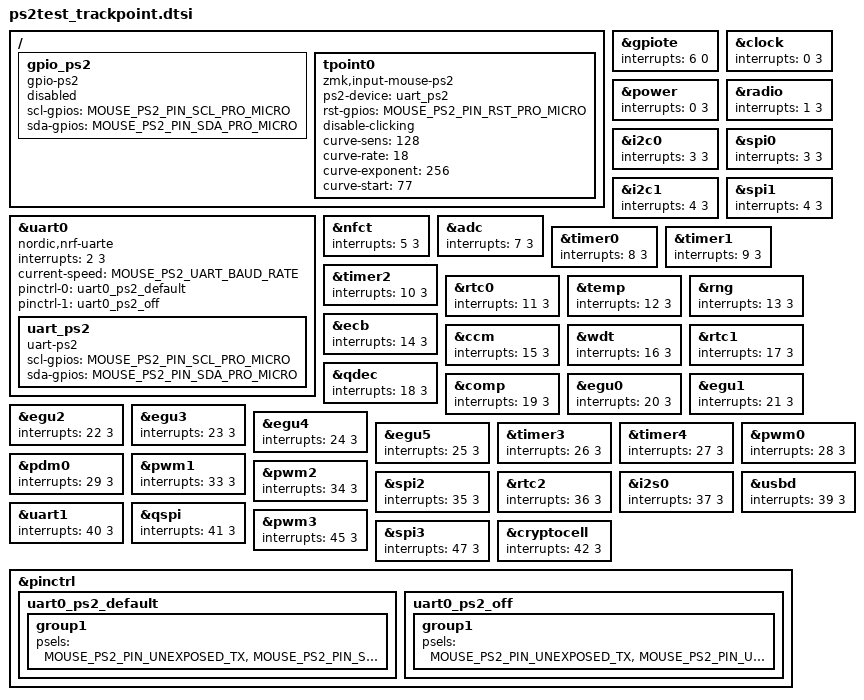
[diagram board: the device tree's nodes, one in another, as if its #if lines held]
/*
 * Direct PS/2 trackpoint wiring for the nice_nano v2 (Exp68 + Exp78).
 *
 * Exp78: switched to the uart-ps2 backend @ 19200 baud. The UART trick
 * glitched at 9600/14400 on THIS trackpoint (jittery RC clock), but 19200
 * was NEVER tried - this experiment is the clean test of that rate.
 * This TP rejects EVERY host command (Exp06): NO_HOST_COMMANDS stays on and
 * the driver never writes; all decode handling lives driver-side.
 *
 * Wiring (fixed empirically - the bench wiring is REVERSED vs stock dabao):
 *   TrackPoint DAT -> P0.08  (pro_micro 0)  = uart0 RX via pinctrl below
 *   TrackPoint CLK -> P0.06  (pro_micro 1)  = scl-gpios (GPIO input)
 *   TrackPoint RST -> float
 *
 * Pull-ups: PS/2 lines are open-drain; the uart backend pulls CLK
 * internally (patched in ps2_uart.c) and DAT idles high.
 */

#include <dt-bindings/pinctrl/nrf-pinctrl.h>

#define MOUSE_PS2_PIN_SCL_PRO_MICRO <&pro_micro 1 GPIO_ACTIVE_HIGH>
#define MOUSE_PS2_PIN_SDA_PRO_MICRO <&pro_micro 0 GPIO_ACTIVE_HIGH>
// #define MOUSE_PS2_PIN_RST_PRO_MICRO <&pro_micro 8 GPIO_ACTIVE_HIGH>

/* Exp78: uart-ps2 @ 19200 - the UART RX pin IS the PS/2 DAT line (P0.08).
 * UART TX / off-state pins are parked on unexposed P0.27: TX is never
 * exercised (NO_HOST_COMMANDS refuses every write) and the off state only
 * exists so the UARTE can release DAT if a write were ever attempted. */
#define MOUSE_PS2_PIN_SDA_PINCTRL <NRF_PSEL(UART_RX, 0, 8)>
#define MOUSE_PS2_UART_BAUD_RATE <19200>
#define MOUSE_PS2_PIN_UNEXPOSED_TX <NRF_PSEL(UART_TX, 0, 27)>
#define MOUSE_PS2_PIN_UNEXPOSED_RX <NRF_PSEL(UART_RX, 0, 27)>

// The Kconfig for both ps2 backends requires these interrupt-priority
// overrides: GPIOTE at the highest priority, everything else at 3, so BT
// controller interrupts never delay the PS/2 processing.
&gpiote { interrupts = < 6 0 >; };
&clock { interrupts = < 0 3 >; };
&power { interrupts = < 0 3 >; };
&radio { interrupts = < 1 3 >; };
&uart0 { interrupts = < 2 3 >; };
&i2c0 { interrupts = < 3 3 >; };
&spi0 { interrupts = < 3 3 >; };
&i2c1 { interrupts = < 4 3 >; };
&spi1 { interrupts = < 4 3 >; };
&nfct { interrupts = < 5 3 >; };
&adc { interrupts = < 7 3 >; };
&timer0 { interrupts = < 8 3 >; };
&timer1 { interrupts = < 9 3 >; };
&timer2 { interrupts = < 10 3 >; };
&rtc0 { interrupts = < 11 3 >; };
&temp { interrupts = < 12 3 >; };
&rng { interrupts = < 13 3 >; };
&ecb { interrupts = < 14 3 >; };
&ccm { interrupts = < 15 3 >; };
&wdt { interrupts = < 16 3 >; };
&rtc1 { interrupts = < 17 3 >; };
&qdec { interrupts = < 18 3 >; };
&comp { interrupts = < 19 3 >; };
&egu0 { interrupts = < 20 3 >; };
&egu1 { interrupts = < 21 3 >; };
&egu2 { interrupts = < 22 3 >; };
&egu3 { interrupts = < 23 3 >; };
&egu4 { interrupts = < 24 3 >; };
&egu5 { interrupts = < 25 3 >; };
&timer3 { interrupts = < 26 3 >; };
&timer4 { interrupts = < 27 3 >; };
&pwm0 { interrupts = < 28 3 >; };
&pdm0 { interrupts = < 29 3 >; };
&pwm1 { interrupts = < 33 3 >; };
&pwm2 { interrupts = < 34 3 >; };
&spi2 { interrupts = < 35 3 >; };
&rtc2 { interrupts = < 36 3 >; };
&i2s0 { interrupts = < 37 3 >; };
&usbd { interrupts = < 39 3 >; };
&uart1 { interrupts = < 40 3 >; };
&qspi { interrupts = < 41 3 >; };
&pwm3 { interrupts = < 45 3 >; };
&spi3 { interrupts = < 47 3 >; };
&cryptocell { interrupts = < 42 3 >; };

/ {
    gpio_ps2: gpio_ps2 {
        status = "disabled";
        compatible = "gpio-ps2";
        scl-gpios = MOUSE_PS2_PIN_SCL_PRO_MICRO;
        sda-gpios = MOUSE_PS2_PIN_SDA_PRO_MICRO;
    };
};

/* Exp78: uart-ps2 backend on uart0 (baud 19200). Mirror of the proven
 * justinmklam dabao structure, adapted to this bench's pin truth:
 *   default: UART RX = DAT P0.08, TX parked on unexposed P0.27
 *   sleep/off: both pins unexposed (releases DAT for GPIO write mode -
 *   unused here since NO_HOST_COMMANDS never writes, but required by the
 *   driver's pinctrl state machine). */
&pinctrl {
    uart0_ps2_default: uart0_ps2_default {
        group1 {
            psels = MOUSE_PS2_PIN_UNEXPOSED_TX,
                            MOUSE_PS2_PIN_SDA_PINCTRL;
        };
    };

    uart0_ps2_off: uart0_ps2_off {
        group1 {
            psels = MOUSE_PS2_PIN_UNEXPOSED_TX,
                            MOUSE_PS2_PIN_UNEXPOSED_RX;
        };
    };
};

&uart0 {
    status = "disabled";
    compatible = "nordic,nrf-uarte";

    current-speed = MOUSE_PS2_UART_BAUD_RATE;
    pinctrl-0 = <&uart0_ps2_default>;
    pinctrl-1 = <&uart0_ps2_off>;
    pinctrl-names = "default", "sleep";

    uart_ps2: uart_ps2 {
        status = "disabled";
        compatible = "uart-ps2";
        scl-gpios = MOUSE_PS2_PIN_SCL_PRO_MICRO;
        sda-gpios = MOUSE_PS2_PIN_SDA_PRO_MICRO;
    };
};

/ {
    tpoint0: tpoint0 {
        status = "disabled";
        compatible = "zmk,input-mouse-ps2";
        ps2-device = <&uart_ps2>;
#ifdef MOUSE_PS2_PIN_RST_PRO_MICRO
        rst-gpios = MOUSE_PS2_PIN_RST_PRO_MICRO;
#endif
    };
};

&uart0 {
    status = "okay";
};
&uart_ps2 {
    status = "okay";
};
&tpoint0 {
    status = "okay";
    // No tp-* / sampling-rate / scroll-mode props on purpose:
    // they would send host commands, which this trackpoint rejects
    // (and NO_HOST_COMMANDS mode makes them no-ops anyway).
    // Clicks disabled: decode noise triggers phantom presses (user req).
    disable-clicking;

    // pr-verify: on-device PowerCurve (Exp60/61 tuning), enabled because
    // curve-rate != 0 and CONFIG_ZMK_INPUT_MOUSE_PS2_POWER_CURVE=y.
    curve-sens = <128>;
    curve-rate = <18>;
    curve-exponent = <256>;
    curve-start = <77>;
};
